# RP2350 register map
Vendor: Raspberry Pi; File version: 0.1
CPU: CM33 r1p0, little endian, MPU, FPU, VTOR, 4 interrupt priority bits, 54 interrupts, 8 SAU regions
Registers are 32-bit, read-write, reset 0x0 unless marked. A register's access mark holds for its fields unless they carry their own. Offsets are from the block's base; [hi:lo] are bit positions; 'fields as' and 'values as' point back to an identical list; <NAME> marks a mode.

## PADS_QSPI
Base 0x40040000
0x00 VOLTAGE_SELECT — Voltage select. Per bank control
  [0] VOLTAGE_SELECT
    0=3v3 (Set voltage to 3.3V (DVDD >= 2V5)); 1=1v8 (Set voltage to 1.8V (DVDD <= 1V8))
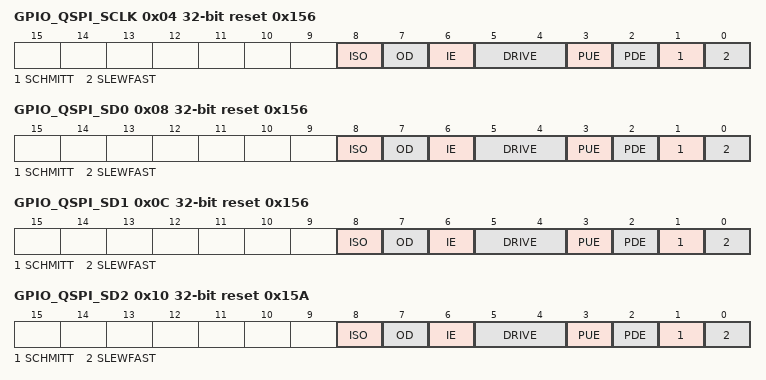
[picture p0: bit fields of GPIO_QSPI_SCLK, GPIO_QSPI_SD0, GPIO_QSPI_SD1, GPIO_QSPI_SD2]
0x04 GPIO_QSPI_SCLK reset 0x156
  [8] ISO — Pad isolation control. Remove this once the pad is configured by software.
  [7] OD — Output disable. Has priority over output enable from peripherals
  [6] IE — Input enable
  [5:4] DRIVE — Drive strength.
    0=2mA; 1=4mA; 2=8mA; 3=12mA
  [3] PUE — Pull up enable
  [2] PDE — Pull down enable
  [1] SCHMITT — Enable schmitt trigger
  [0] SLEWFAST — Slew rate control. 1 = Fast, 0 = Slow
0x08 GPIO_QSPI_SD0 reset 0x156
  fields as GPIO_QSPI_SCLK
0x0C GPIO_QSPI_SD1 reset 0x156
  fields as GPIO_QSPI_SCLK
0x10 GPIO_QSPI_SD2 reset 0x15A
  fields as GPIO_QSPI_SCLK
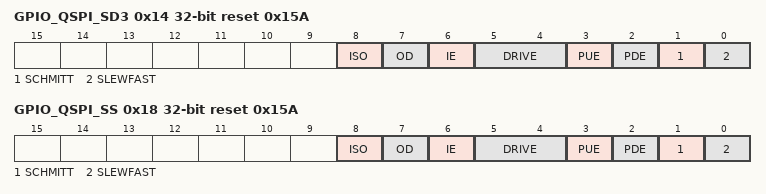
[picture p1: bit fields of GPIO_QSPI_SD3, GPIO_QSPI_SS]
0x14 GPIO_QSPI_SD3 reset 0x15A
  fields as GPIO_QSPI_SCLK
0x18 GPIO_QSPI_SS reset 0x15A
  fields as GPIO_QSPI_SCLK

## XOSC — Controls the crystal oscillator
Base 0x40048000
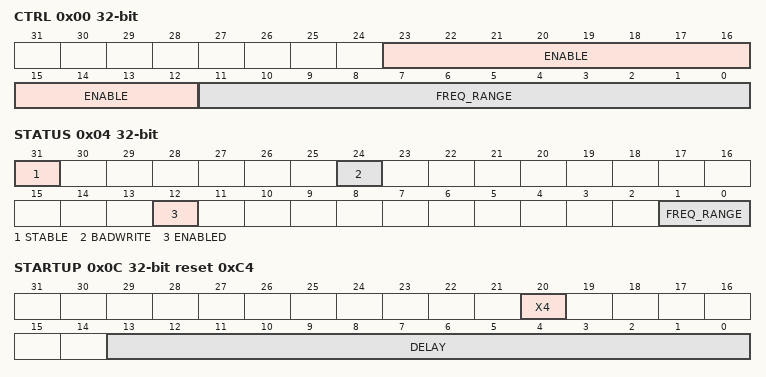
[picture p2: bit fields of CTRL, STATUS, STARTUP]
0x00 CTRL — Crystal Oscillator Control
  [23:12] ENABLE — On power-up this field is initialised to DISABLE and the chip runs from the ROSC. If the chip has subsequently been programmed to run from the XOSC then setting this field to DISABLE may lock-up the chip. If this is a concern then run the clk_ref from the ROSC and enable the clk_sys RESUS feature. The 12-bit code is intended to give some protection against accidental writes. An invalid setting will retain the previous value. The actual value being used can be read from STATUS_ENABLED
    0xD1E=DISABLE; 0xFAB=ENABLE
  [11:0] FREQ_RANGE — The 12-bit code is intended to give some protection against accidental writes. An invalid setting will retain the previous value. The actual value being used can be read from STATUS_FREQ_RANGE
    0xAA0=1_15MHZ; 0xAA1=10_30MHZ; 0xAA2=25_60MHZ; 0xAA3=40_100MHZ
0x04 STATUS access per field — Crystal Oscillator Status
  [31] STABLE ro — Oscillator is running and stable
  [24] BADWRITE rw write-1-clears — An invalid value has been written to CTRL_ENABLE or CTRL_FREQ_RANGE or DORMANT
  [12] ENABLED ro — Oscillator is enabled but not necessarily running and stable, resets to 0
  [1:0] FREQ_RANGE ro — The current frequency range setting
    0=1_15MHZ; 1=10_30MHZ; 2=25_60MHZ; 3=40_100MHZ
0x08 DORMANT — Crystal Oscillator pause control. This is used to save power by pausing the XOSC. On power-up this field is initialised to WAKE. An invalid write will also select WAKE. WARNING: stop the PLLs before selecting dormant mode. WARNING: setup the irq before selecting dormant mode
0x0C STARTUP reset 0xC4 — Controls the startup delay
  [20] X4 — Multiplies the startup_delay by 4, just in case. The reset value is controlled by a mask-programmable tiecell and is provided in case we are booting from XOSC and the default startup delay is insufficient
  [13:0] DELAY — in multiples of 256*xtal_period. The reset value of 0xc4 corresponds to approx 50 000 cycles.
0x10 COUNT — A down counter running at the xosc frequency which counts to zero and stops. Can be used for short software pauses when setting up time sensitive hardware. To start the counter, write a non-zero value. Reads will return 1 while the count is running and 0 when it has finished. Minimum count value is 4. Count values <4 will be treated as count value =4. Note that synchronisation to the register clock domain costs 2 register clock cycles and the counter cannot compensate for that.
  [15:0] COUNT

## PLL_SYS
Base 0x40050000
Same registers: PLL_USB 0x40058000
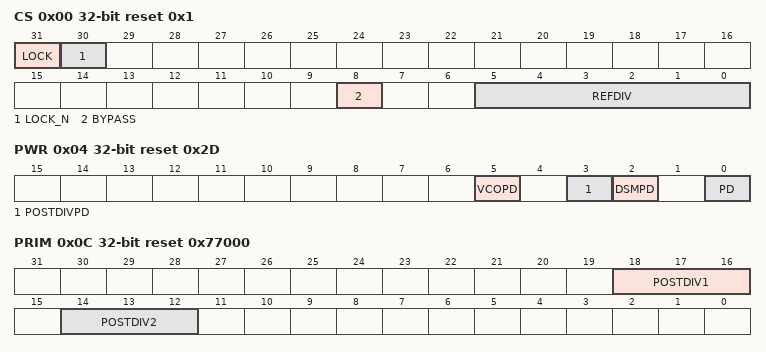
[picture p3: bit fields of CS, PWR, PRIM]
0x00 CS access per field reset 0x1 — Control and Status. GENERAL CONSTRAINTS: Reference clock frequency min=5MHz, max=800MHz. Feedback divider min=16, max=320. VCO frequency min=400MHz, max=1600MHz
  [31] LOCK ro — PLL is locked
  [30] LOCK_N rw write-1-clears — PLL is not locked. Ideally this is cleared when PLL lock is seen and this should never normally be set
  [8] BYPASS rw — Passes the reference clock to the output instead of the divided VCO. The VCO continues to run so the user can switch between the reference clock and the divided VCO but the output will glitch when doing so.
  [5:0] REFDIV rw — Divides the PLL input reference clock. Behaviour is undefined for div=0. PLL output will be unpredictable during refdiv changes, wait for lock=1 before using it.
0x04 PWR reset 0x2D — Controls the PLL power modes.
  [5] VCOPD — PLL VCO powerdown. To save power set high when PLL output not required or bypass=1.
  [3] POSTDIVPD — PLL post divider powerdown. To save power set high when PLL output not required or bypass=1.
  [2] DSMPD — PLL DSM powerdown. Nothing is achieved by setting this low.
  [0] PD — PLL powerdown. To save power set high when PLL output not required.
0x08 FBDIV_INT — Feedback divisor (note: this PLL does not support fractional division)
  [11:0] FBDIV_INT — see ctrl reg description for constraints
0x0C PRIM reset 0x77000 — Controls the PLL post dividers for the primary output (note: this PLL does not have a secondary output) the primary output is driven from VCO divided by postdiv1*postdiv2
  [18:16] POSTDIV1 — divide by 1-7
  [14:12] POSTDIV2 — divide by 1-7
0x10 INTR — Raw Interrupts
  [0] LOCK_N_STICKY write-1-clears
0x14 INTE — Interrupt Enable
  [0] LOCK_N_STICKY
0x18 INTF — Interrupt Force
  [0] LOCK_N_STICKY
0x1C INTS ro — Interrupt status after masking & forcing
  [0] LOCK_N_STICKY
